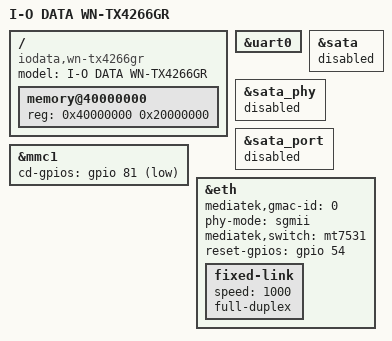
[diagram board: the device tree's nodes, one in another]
// SPDX-License-Identifier: GPL-2.0
/dts-v1/;

#include "mt7622.dtsi"
#include "mt7622-u-boot.dtsi"

/ {
	model = "I-O DATA WN-TX4266GR";
	compatible = "iodata,wn-tx4266gr", "mediatek,mt7622";

	memory@40000000 {
		device_type = "memory";
		reg = <0x40000000 0x20000000>;
	};
};

&uart0 {
	status = "okay";
};

&mmc1 {
	status = "okay";

	cd-gpios = <&gpio 81 GPIO_ACTIVE_LOW>;
};

&sata {
	status = "disabled";
};

&sata_phy {
	status = "disabled";
};

&sata_port {
	status = "disabled";
};

&eth {
	status = "okay";

	mediatek,gmac-id = <0>;
	phy-mode = "sgmii";

	mediatek,switch = "mt7531";
	reset-gpios = <&gpio 54 GPIO_ACTIVE_HIGH>;

	fixed-link {
		speed = <1000>;
		full-duplex;
	};
};
